VERSION ""

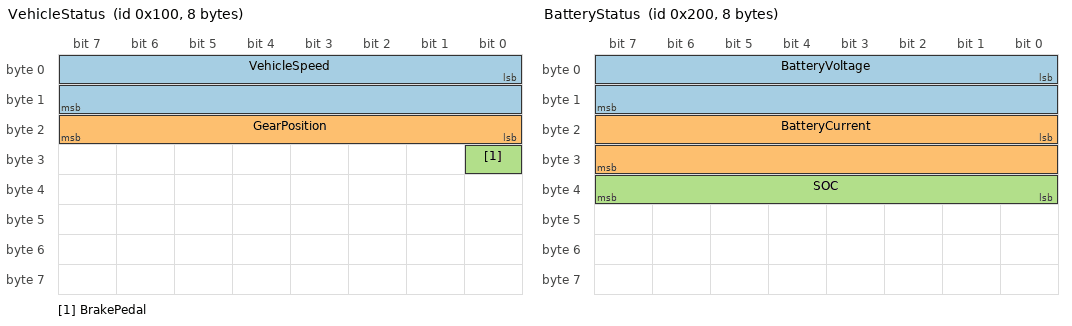
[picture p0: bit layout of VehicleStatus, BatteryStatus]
BO_ 256 VehicleStatus: 8 Vector__XXX
 SG_ VehicleSpeed : 0|16@1+ (0.1,0) [0|250] "km/h" Vector__XXX
 SG_ GearPosition : 16|8@1+ (1,0) [0|7] "" Vector__XXX
 SG_ BrakePedal : 24|1@1+ (1,0) [0|1] "" Vector__XXX

BO_ 512 BatteryStatus: 8 Vector__XXX
 SG_ BatteryVoltage : 0|16@1+ (0.01,0) [0|65.535] "V" Vector__XXX
 SG_ BatteryCurrent : 16|16@1+ (0.1,-3276.8) [-3276.8|3276.7] "A" Vector__XXX
 SG_ SOC : 32|8@1+ (0.5,0) [0|100] "%" Vector__XXX
